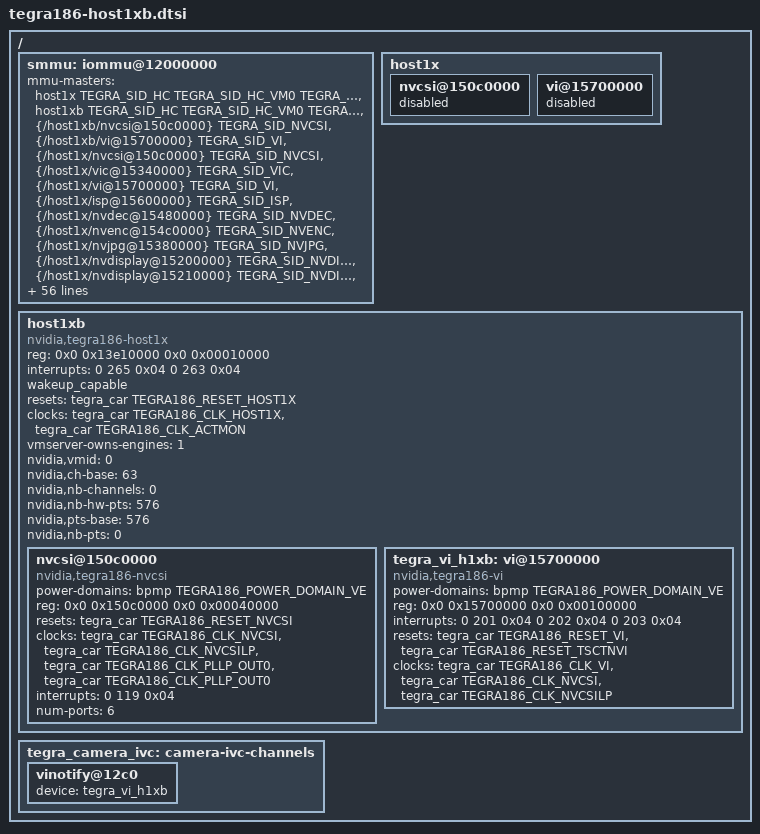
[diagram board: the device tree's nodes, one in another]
/*
 * tegra186-host1xb.dtsi: Configure host1xb
 *
 * Copyright (c) 2017, NVIDIA CORPORATION.  All rights reserved.
 *
 * This program is free software; you can redistribute it and/or modify
 * it under the terms of the GNU General Public License as published by
 * the Free Software Foundation; version 2 of the License.
 *
 * This program is distributed in the hope that it will be useful, but WITHOUT
 * ANY WARRANTY; without even the implied warranty of MERCHANTABILITY or
 * FITNESS FOR A PARTICULAR PURPOSE.  See the GNU General Public License for
 * more details.
 */

/ {
	smmu: iommu@12000000{
		mmu-masters = <&host1x				TEGRA_SID_HC
								TEGRA_SID_HC_VM0
								TEGRA_SID_HC_VM1
								TEGRA_SID_HC_VM2
								TEGRA_SID_HC_VM3
								TEGRA_SID_HC_VM4
								TEGRA_SID_HC_VM5
								TEGRA_SID_HC_VM6
								TEGRA_SID_HC_VM7>,
				<&host1xb			TEGRA_SID_HC
								TEGRA_SID_HC_VM0
								TEGRA_SID_HC_VM1
								TEGRA_SID_HC_VM2
								TEGRA_SID_HC_VM3
								TEGRA_SID_HC_VM4
								TEGRA_SID_HC_VM5
								TEGRA_SID_HC_VM6
								TEGRA_SID_HC_VM7>,
			      <&{/host1xb/nvcsi@150c0000}	TEGRA_SID_NVCSI>,
			      <&{/host1xb/vi@15700000}		TEGRA_SID_VI>,
			      <&{/host1x/nvcsi@150c0000}	TEGRA_SID_NVCSI>,
			      <&{/host1x/vic@15340000}		TEGRA_SID_VIC>,
			      <&{/host1x/vi@15700000}		TEGRA_SID_VI>,
			      <&{/host1x/isp@15600000}		TEGRA_SID_ISP>,
			      <&{/host1x/nvdec@15480000}	TEGRA_SID_NVDEC>,
			      <&{/host1x/nvenc@154c0000}	TEGRA_SID_NVENC>,
			      <&{/host1x/nvjpg@15380000}	TEGRA_SID_NVJPG>,
			      <&{/host1x/nvdisplay@15200000}	TEGRA_SID_NVDISPLAY>,
			      <&{/host1x/nvdisplay@15210000}	TEGRA_SID_NVDISPLAY>,
			      <&{/host1x/nvdisplay@15220000}	TEGRA_SID_NVDISPLAY>,
			      <&{/host1x/tsec@15500000}		TEGRA_SID_TSEC>,
			      <&{/host1x/tsecb@15100000}	TEGRA_SID_TSECB>,
			      <&{/host1x/se@15810000}		TEGRA_SID_SE>,
			      <&{/host1x/se@15820000}		TEGRA_SID_SE1>,
			      <&{/host1x/se@15830000}		TEGRA_SID_SE2>,
			      <&{/host1x/se@15840000}		TEGRA_SID_SE3>,
			      <&{/smmu_test}			TEGRA_SID_SMMU_TEST>,
			      <&{/gp10b}			TEGRA_SID_GPUB>,
			      <&host1x_ctx0			TEGRA_SID_HOST1X_CTX0>,
			      <&host1x_ctx1			TEGRA_SID_HOST1X_CTX1>,
			      <&host1x_ctx2			TEGRA_SID_HOST1X_CTX2>,
			      <&host1x_ctx3			TEGRA_SID_HOST1X_CTX3>,
			      <&host1x_ctx4			TEGRA_SID_HOST1X_CTX4>,
			      <&host1x_ctx5			TEGRA_SID_HOST1X_CTX5>,
			      <&host1x_ctx6			TEGRA_SID_HOST1X_CTX6>,
			      <&host1x_ctx7			TEGRA_SID_HOST1X_CTX7>,

			      /* Non-host devices. */
			      <&{/adsp@2993000}		TEGRA_SID_APE>,
			      <&{/rtcpu@2993000}	TEGRA_SID_RCE>,
			      <&{/ether_qos@2490000}	TEGRA_SID_EQOS>,
			      <&{/sdhci@3460000}	TEGRA_SID_SDMMC4A>,
			      <&{/sdhci@3420000}	TEGRA_SID_SDMMC2A>,
			      <&{/sdhci@3400000}	TEGRA_SID_SDMMC1A>,
			      <&{/ufshci@2450000}	TEGRA_SID_UFSHC>,
			      <&{/xhci@3530000}		TEGRA_SID_XUSB_HOST>,
			      <&{/xudc@3550000}		TEGRA_SID_XUSB_DEV>,
			      <&{/hda@3510000}		TEGRA_SID_HDA>,
			      <&tegra_adsp_audio	TEGRA_SID_APE>,
			      <&{/sound}		TEGRA_SID_APE>,
			      <&{/sound_ref}		TEGRA_SID_APE>,
			      <&{/pcie-controller@10003000} TEGRA_SID_AFI>,
			      <&{/ahci-sata@3507000}	TEGRA_SID_SATA2>,
			      <&{/aon@c160000}		TEGRA_SID_AON>,
			      <&{/rtcpu@b000000}	TEGRA_SID_RCE>,
			      <&{/bpmp}			TEGRA_SID_BPMP>,
			      <&{/dma@2600000}		TEGRA_SID_GPCDMA_0>,
			      <&{/spi@3210000}		TEGRA_SID_GPCDMA_0>,
			      <&{/spi@3230000}		TEGRA_SID_GPCDMA_0>,
			      <&{/spi@3240000}		TEGRA_SID_GPCDMA_0>,
			      <&{/spi@3270000}		TEGRA_SID_GPCDMA_0>,
			      <&{/spi@c260000}		TEGRA_SID_GPCDMA_0>,
			      <&{/serial@3100000}	TEGRA_SID_GPCDMA_0>,
			      <&{/serial@3110000}	TEGRA_SID_GPCDMA_0>,
			      <&{/serial@c280000}	TEGRA_SID_GPCDMA_0>,
			      <&{/serial@3130000}	TEGRA_SID_GPCDMA_0>,
			      <&{/serial@3140000}	TEGRA_SID_GPCDMA_0>,
			      <&{/serial@3150000}	TEGRA_SID_GPCDMA_0>,
			      <&{/serial@c290000}	TEGRA_SID_GPCDMA_0>,
			      <&{/i2c@3160000}		TEGRA_SID_GPCDMA_0>,
			      <&{/i2c@c240000}		TEGRA_SID_GPCDMA_0>,
			      <&{/i2c@3180000}		TEGRA_SID_GPCDMA_0>,
			      <&{/i2c@3190000}		TEGRA_SID_GPCDMA_0>,
			      <&{/i2c@31b0000}		TEGRA_SID_GPCDMA_0>,
			      <&{/i2c@31c0000}		TEGRA_SID_GPCDMA_0>,
			      <&{/i2c@c250000}		TEGRA_SID_GPCDMA_0>,
			      <&{/i2c@31e0000}		TEGRA_SID_GPCDMA_0>;
		};

	host1x {
		nvcsi@150c0000 {
			status = "disabled";
		};

		vi@15700000 {
			status = "disabled";
		};
	};

	host1xb: host1xb {
		compatible = "nvidia,tegra186-host1x", "simple-bus";
		reg = <0x0 0x13e10000 0x0 0x00010000>;
		interrupts = <0 265 0x04
			      0 263 0x04>;
		wakeup_capable;
		resets = <&tegra_car TEGRA186_RESET_HOST1X>;
		clocks = <&tegra_car TEGRA186_CLK_HOST1X>,
			 <&tegra_car TEGRA186_CLK_ACTMON>;
		clock-names = "host1x", "actmon";
		status = "okay";

                #address-cells = <2>;
                #size-cells = <2>;

		#stream-id-cells = <9>;

		ranges;

		vmserver-owns-engines = <1>;

		nvidia,vmid = <0>;

		nvidia,ch-base = <63>;
		nvidia,nb-channels = <0>;

		nvidia,nb-hw-pts = <576>;
		nvidia,pts-base = <576>;
		nvidia,nb-pts = <0>;

		nvcsi@150c0000 {
			compatible = "nvidia,tegra186-nvcsi";
			power-domains = <&bpmp TEGRA186_POWER_DOMAIN_VE>;
			reg = <0x0 0x150c0000 0x0 0x00040000>;
			resets = <&tegra_car TEGRA186_RESET_NVCSI>;
			clocks = <&tegra_car TEGRA186_CLK_NVCSI>,
				 <&tegra_car TEGRA186_CLK_NVCSILP>,
				 <&tegra_car TEGRA186_CLK_PLLP_OUT0>,
				 <&tegra_car TEGRA186_CLK_PLLP_OUT0>;
			clock-names = "nvcsi", "nvcsilp", "nvcsi_parent",
				      "nvcsilp_parent";
			interrupts = <0 119 0x04>;
			#stream-id-cells = <1>;
			status = "okay";
			num-ports = <6>;
		};

		tegra_vi_h1xb: vi@15700000 {
			compatible = "nvidia,tegra186-vi";
			power-domains = <&bpmp TEGRA186_POWER_DOMAIN_VE>;
                        reg = <0x0 0x15700000 0x0 0x00100000>;
                        interrupts = <0 201 0x04
                                      0 202 0x04
                                      0 203 0x04>;
			resets = <&tegra_car TEGRA186_RESET_VI>,
				 <&tegra_car TEGRA186_RESET_TSCTNVI>;
			reset-names = "vi", "tsctnvi";
			clocks = <&tegra_car TEGRA186_CLK_VI>,
				 <&tegra_car TEGRA186_CLK_NVCSI>,
				 <&tegra_car TEGRA186_CLK_NVCSILP>;
			clock-names = "vi", "nvcsi", "nvcsilp";
			#stream-id-cells = <1>;
			status = "okay";
		};
	};

	tegra_camera_ivc: camera-ivc-channels {
		vinotify@12c0 {
			device = <&tegra_vi_h1xb>;
		};
	};
};
